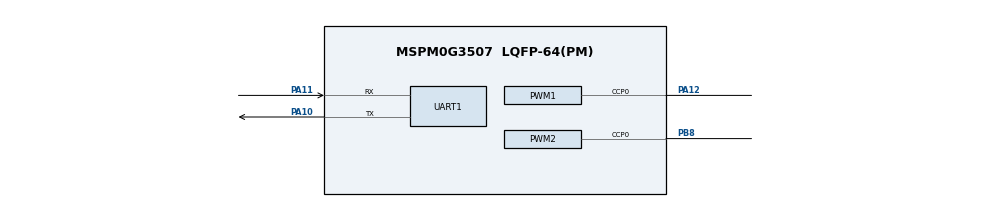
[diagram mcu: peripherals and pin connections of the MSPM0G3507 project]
/**
 * These arguments were used when this file was generated. They will be automatically applied on subsequent loads
 * via the GUI or CLI. Run CLI with '--help' for additional information on how to override these arguments.
 * @cliArgs --device "MSPM0G350X" --part "Default" --package "LQFP-64(PM)" --product "mspm0_sdk@2.02.00.05"
 * @v2CliArgs --device "MSPM0G3507" --package "LQFP-64(PM)" --product "mspm0_sdk@2.02.00.05"
 * @versions {"tool":"1.21.1+3772"}
 */

/**
 * Import the modules used in this configuration.
 */
const GPIO    = scripting.addModule("/ti/driverlib/GPIO", {}, false);
const GPIO1   = GPIO.addInstance();
const GPIO2   = GPIO.addInstance();
const PWM     = scripting.addModule("/ti/driverlib/PWM", {}, false);
const PWM1    = PWM.addInstance();
const PWM2    = PWM.addInstance();
const SYSCTL  = scripting.addModule("/ti/driverlib/SYSCTL");
const SYSTICK = scripting.addModule("/ti/driverlib/SYSTICK");
const UART    = scripting.addModule("/ti/driverlib/UART", {}, false);
const UART1   = UART.addInstance();

/**
 * Write custom configuration values to the imported modules.
 */
GPIO1.$name                              = "KEY";
GPIO1.associatedPins.create(5);
GPIO1.associatedPins[0].$name            = "DOWN";
GPIO1.associatedPins[0].direction        = "INPUT";
GPIO1.associatedPins[0].interruptEn      = true;
GPIO1.associatedPins[0].polarity         = "RISE";
GPIO1.associatedPins[0].internalResistor = "PULL_UP";
GPIO1.associatedPins[0].assignedPort     = "PORTA";
GPIO1.associatedPins[0].assignedPin      = "28";
GPIO1.associatedPins[1].$name            = "UP";
GPIO1.associatedPins[1].direction        = "INPUT";
GPIO1.associatedPins[1].internalResistor = "PULL_UP";
GPIO1.associatedPins[1].assignedPort     = "PORTA";
GPIO1.associatedPins[1].assignedPin      = "9";
GPIO1.associatedPins[1].polarity         = "RISE";
GPIO1.associatedPins[2].$name            = "LEFT";
GPIO1.associatedPins[2].direction        = "INPUT";
GPIO1.associatedPins[2].internalResistor = "PULL_UP";
GPIO1.associatedPins[2].assignedPort     = "PORTA";
GPIO1.associatedPins[2].assignedPin      = "8";
GPIO1.associatedPins[2].polarity         = "RISE";
GPIO1.associatedPins[3].$name            = "RIGHT";
GPIO1.associatedPins[3].direction        = "INPUT";
GPIO1.associatedPins[3].internalResistor = "PULL_UP";
GPIO1.associatedPins[3].assignedPort     = "PORTA";
GPIO1.associatedPins[3].assignedPin      = "31";
GPIO1.associatedPins[3].polarity         = "RISE";
GPIO1.associatedPins[4].$name            = "MID";
GPIO1.associatedPins[4].direction        = "INPUT";
GPIO1.associatedPins[4].internalResistor = "PULL_UP";
GPIO1.associatedPins[4].assignedPort     = "PORTB";
GPIO1.associatedPins[4].assignedPin      = "4";
GPIO1.associatedPins[4].interruptEn      = true;
GPIO1.associatedPins[4].polarity         = "RISE";

const Board = scripting.addModule("/ti/driverlib/Board", {}, false);

GPIO2.$name                          = "LED";
GPIO2.associatedPins[0].$name        = "GREEN";
GPIO2.associatedPins[0].assignedPort = "PORTB";
GPIO2.associatedPins[0].assignedPin  = "22";

PWM1.$name                              = "SG90";
PWM1.clockDivider                       = 8;
PWM1.clockPrescale                      = 200;
PWM1.timerCount                         = 40;
PWM1.timerStartTimer                    = true;
PWM1.ccIndex                            = [0];
PWM1.peripheral.ccp0Pin.$assign         = "PA12";
PWM1.PWM_CHANNEL_0.$name                = "ti_driverlib_pwm_PWMTimerCC0";
PWM1.PWM_CHANNEL_0.invert               = true;
PWM1.ccp0PinConfig.$name                = "ti_driverlib_gpio_GPIOPinGeneric2";
PWM1.ccp0PinConfig.direction            = scripting.forceWrite("OUTPUT");
PWM1.ccp0PinConfig.hideOutputInversion  = scripting.forceWrite(false);
PWM1.ccp0PinConfig.onlyInternalResistor = scripting.forceWrite(false);
PWM1.ccp0PinConfig.passedPeripheralType = scripting.forceWrite("Digital");

PWM2.$name                              = "SG90S";
PWM2.clockDivider                       = 8;
PWM2.clockPrescale                      = 200;
PWM2.timerCount                         = 400;
PWM2.timerStartTimer                    = true;
PWM2.ccIndex                            = [0];
PWM2.peripheral.ccp0Pin.$assign         = "PB8";
PWM2.PWM_CHANNEL_0.$name                = "ti_driverlib_pwm_PWMTimerCC2";
PWM2.PWM_CHANNEL_0.invert               = true;
PWM2.ccp0PinConfig.$name                = "ti_driverlib_gpio_GPIOPinGeneric4";
PWM2.ccp0PinConfig.direction            = scripting.forceWrite("OUTPUT");
PWM2.ccp0PinConfig.hideOutputInversion  = scripting.forceWrite(false);
PWM2.ccp0PinConfig.onlyInternalResistor = scripting.forceWrite(false);
PWM2.ccp0PinConfig.passedPeripheralType = scripting.forceWrite("Digital");

SYSCTL.forceDefaultClkConfig = true;

SYSTICK.period = 32000;

UART1.$name                    = "UART_0";
UART1.peripheral.rxPin.$assign = "PA11";
UART1.peripheral.txPin.$assign = "PA10";
UART1.txPinConfig.$name        = "ti_driverlib_gpio_GPIOPinGeneric0";
UART1.rxPinConfig.$name        = "ti_driverlib_gpio_GPIOPinGeneric1";

/**
 * Pinmux solution for unlocked pins/peripherals. This ensures that minor changes to the automatic solver in a future
 * version of the tool will not impact the pinmux you originally saw.  These lines can be completely deleted in order to
 * re-solve from scratch.
 */
GPIO1.associatedPins[0].pin.$suggestSolution = "PA28";
GPIO1.associatedPins[1].pin.$suggestSolution = "PA9";
GPIO1.associatedPins[2].pin.$suggestSolution = "PA8";
GPIO1.associatedPins[3].pin.$suggestSolution = "PA31";
GPIO1.associatedPins[4].pin.$suggestSolution = "PB4";
Board.peripheral.$suggestSolution            = "DEBUGSS";
Board.peripheral.swclkPin.$suggestSolution   = "PA20";
Board.peripheral.swdioPin.$suggestSolution   = "PA19";
GPIO2.associatedPins[0].pin.$suggestSolution = "PB22";
PWM1.peripheral.$suggestSolution             = "TIMG0";
PWM2.peripheral.$suggestSolution             = "TIMA0";
SYSCTL.peripheral.$suggestSolution           = "SYSCTL";
UART1.peripheral.$suggestSolution            = "UART0";
